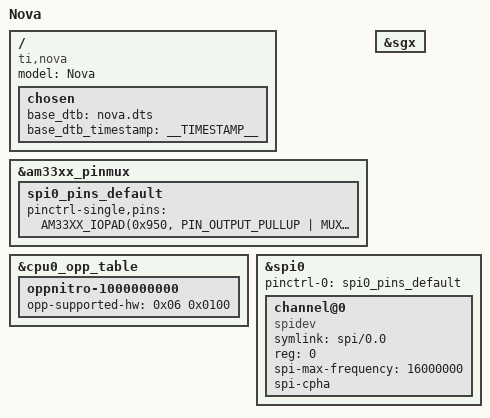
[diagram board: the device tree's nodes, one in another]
// SPDX-License-Identifier: GPL-2.0-only
/*
 * Copyright (C) 2012 Texas Instruments Incorporated - http://www.ti.com/
 */
/dts-v1/;

#include "am33xx.dtsi"
#include "am335x-bone-common.dtsi"
#include "am335x-boneblack-common.dtsi"
/* #include "am335x-bone-jtag.dtsi" */

/ {
	model = "Nova";
	compatible = "ti,nova", "ti,am335x-bone", "ti,am33xx";

	chosen {
		base_dtb = "nova.dts";
		base_dtb_timestamp = __TIMESTAMP__;
	};
};

&am33xx_pinmux {
	spi0_pins_default: spi0_pins_default {
		pinctrl-single,pins = <
			AM33XX_IOPAD(0x950, PIN_OUTPUT_PULLUP | MUX_MODE0) /* (A18) spi0_sclk.spi0_sclk */
			AM33XX_IOPAD(0x954, PIN_INPUT_PULLUP  | MUX_MODE0) /* (B18) spi0_d0.spi0_d0 */
			AM33XX_IOPAD(0x958, PIN_OUTPUT_PULLUP | MUX_MODE0) /* (B17) spi0_d1.spi0_d1 */
			AM33XX_IOPAD(0x95c, PIN_OUTPUT_PULLUP | MUX_MODE0) /* (A17) spi0_cs0.spi0_cs0 */
		>;
	};
};

&sgx {
	status = "okay";
};

&cpu0_opp_table {
	/*
	 * All PG 2.0 silicon may not support 1GHz but some of the early
	 * BeagleBone Blacks have PG 2.0 silicon which is guaranteed
	 * to support 1GHz OPP so enable it for PG 2.0 on this board.
	 */
	oppnitro-1000000000 {
		opp-supported-hw = <0x06 0x0100>;
	};
};

&spi0 {
	status = "okay";
	pinctrl-names = "default";
	pinctrl-0 = <&spi0_pins_default>;

	channel@0 {
		#address-cells = <1>;
		#size-cells = <0>;

		compatible = "spidev";
		symlink = "spi/0.0";

		reg = <0>;
		spi-max-frequency = <16000000>;
		spi-cpha;
        };
};
